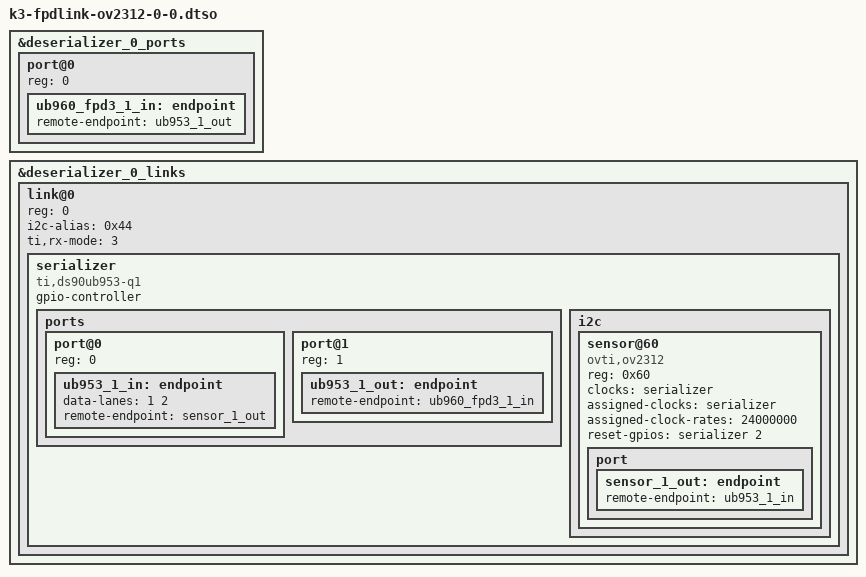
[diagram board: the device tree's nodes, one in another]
// SPDX-License-Identifier: GPL-2.0
/*
 * IMX390 FPD-Link 3 Camera Module
 * Copyright (c) 2023 Texas Instruments Incorporated - http://www.ti.com/
 */

/dts-v1/;
/plugin/;

#include <dt-bindings/gpio/gpio.h>

&deserializer_0_ports {
	#address-cells = <1>;
	#size-cells = <0>;

	/* FPDLink RX 0 */
	port@0 {
		reg = <0>;

		ub960_fpd3_1_in: endpoint {
			remote-endpoint = <&ub953_1_out>;
		};
	};
};

&deserializer_0_links {
	#address-cells = <1>;
	#size-cells = <0>;

	link@0 {
		reg = <0>;
		i2c-alias = <0x44>;

		ti,rx-mode = <3>;

		serializer: serializer {
			compatible = "ti,ds90ub953-q1";
			gpio-controller;
			#gpio-cells = <2>;

			#clock-cells = <0>;

			ports {
				#address-cells = <1>;
				#size-cells = <0>;

				port@0 {
					reg = <0>;
					ub953_1_in: endpoint {
						data-lanes = <1 2>;
						/*clock-noncontinuous;*/
						remote-endpoint = <&sensor_1_out>;
					};
				};

				port@1 {
					reg = <1>;

					ub953_1_out: endpoint {
						remote-endpoint = <&ub960_fpd3_1_in>;
					};
				};
			};

			i2c {
				#address-cells = <1>;
				#size-cells = <0>;

				sensor@60 {
					compatible = "ovti,ov2312";
					reg = <0x60>;

					clocks = <&serializer>;
					clock-names = "xvclk";
					assigned-clocks = <&serializer>;
					assigned-clock-rates = <24000000>;

					reset-gpios = <&serializer 2 GPIO_ACTIVE_HIGH>;

					port {
						sensor_1_out: endpoint {
							remote-endpoint = <&ub953_1_in>;
						};
					};
				};
			};
		};
	};
};
